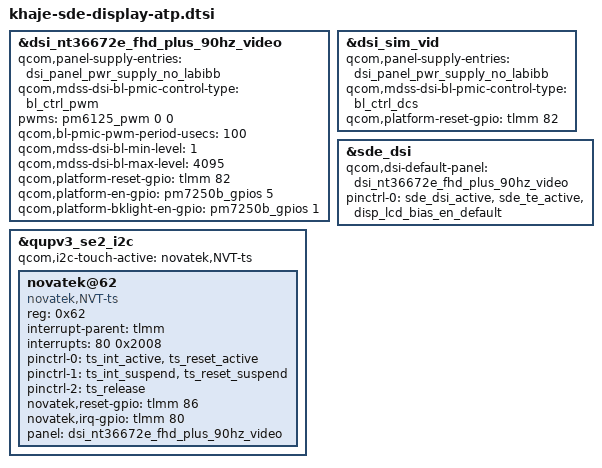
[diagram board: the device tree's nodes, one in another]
#include "khaje-sde-display.dtsi"
&dsi_nt36672e_fhd_plus_90hz_video {
        qcom,panel-supply-entries = <&dsi_panel_pwr_supply_no_labibb>;
        qcom,mdss-dsi-bl-pmic-control-type = "bl_ctrl_pwm";
        pwms = <&pm6125_pwm 0 0>;
        qcom,bl-pmic-pwm-period-usecs = <100>;
        qcom,mdss-dsi-bl-min-level = <1>;
        qcom,mdss-dsi-bl-max-level = <4095>;
        qcom,platform-reset-gpio = <&tlmm 82 0>;
        qcom,platform-en-gpio = <&pm7250b_gpios 5 0>;
        qcom,platform-bklight-en-gpio = <&pm7250b_gpios 1 0>;
        /delete-property/ qcom,esd-check-enabled;
};

&dsi_sim_vid {
        qcom,panel-supply-entries = <&dsi_panel_pwr_supply_no_labibb>;
        qcom,mdss-dsi-bl-pmic-control-type = "bl_ctrl_dcs";
        qcom,platform-reset-gpio = <&tlmm 82 0>;
};

&sde_dsi {
        qcom,dsi-default-panel = <&dsi_nt36672e_fhd_plus_90hz_video>;
        pinctrl-0 = <&sde_dsi_active &sde_te_active &disp_lcd_bias_en_default>;
};

&qupv3_se2_i2c {
        status = "okay";
        qcom,i2c-touch-active="novatek,NVT-ts";

        novatek@62 {
                compatible = "novatek,NVT-ts";
                reg = <0x62>;
                status = "ok";

                interrupt-parent = <&tlmm>;
                interrupts = <80 0x2008>;
                pinctrl-names = "pmx_ts_active","pmx_ts_suspend",
                                "pmx_ts_release";
                pinctrl-0 = <&ts_int_active &ts_reset_active>;
                pinctrl-1 = <&ts_int_suspend &ts_reset_suspend>;
                pinctrl-2 = <&ts_release>;

                novatek,reset-gpio = <&tlmm 86 0x00>;
                novatek,irq-gpio = <&tlmm 80 0x2008>;

                panel = <&dsi_nt36672e_fhd_plus_90hz_video>;
        };
};
